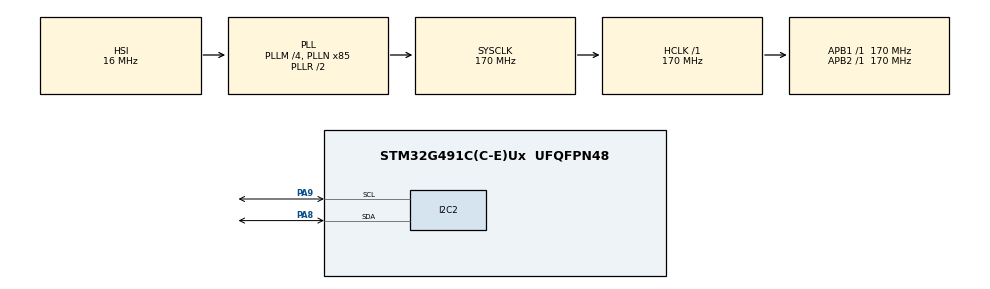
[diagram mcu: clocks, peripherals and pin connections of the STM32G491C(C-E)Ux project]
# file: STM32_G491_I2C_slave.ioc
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I2C2.OwnAddress=0x01
I2C2.Timing=0x30A0A7FB
Mcu.Family=STM32G4
Mcu.Name=STM32G491C(C-E)Ux
Mcu.Package=UFQFPN48
NVIC.I2C2_ER_IRQn=true\:0\:0\:false\:false\:true\:true\:true
NVIC.I2C2_EV_IRQn=true\:0\:0\:false\:false\:true\:true\:true
NVIC.PriorityGroup=NVIC_PRIORITYGROUP_4
PA8.Mode=I2C
PA8.Signal=I2C2_SDA
PA9.Mode=I2C
PA9.Signal=I2C2_SCL
ProjectManager.HeapSize=0x200
ProjectManager.StackSize=0x400
ProjectManager.TargetToolchain=STM32CubeIDE
RCC.ADC12Freq_Value=170000000
RCC.ADC345Freq_Value=170000000
RCC.AHBFreq_Value=170000000
RCC.APB1Freq_Value=170000000
RCC.APB1TimFreq_Value=170000000
RCC.APB2Freq_Value=170000000
RCC.APB2TimFreq_Value=170000000
RCC.CortexFreq_Value=170000000
RCC.EXTERNAL_CLOCK_VALUE=12288000
RCC.HCLKFreq_Value=170000000
RCC.HSE_VALUE=8000000
RCC.HSI48_VALUE=48000000
RCC.HSI_VALUE=16000000
RCC.LSE_VALUE=32768
RCC.PLLM=RCC_PLLM_DIV4
RCC.PLLN=85
RCC.SYSCLKFreq_VALUE=170000000
RCC.SYSCLKSource=RCC_SYSCLKSOURCE_PLLCLK
RCC.USBFreq_Value=48000000
RCC.VCOOutputFreq_Value=340000000
VP_SYS_VS_DBSignals.Mode=DisableDeadBatterySignals
board=custom

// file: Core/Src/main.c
/* USER CODE BEGIN Header */
/**
  ******************************************************************************
  * @file           : main.c
  * @brief          : Main program body
  ******************************************************************************
  * @attention
  *
  * <h2><center>&copy; Copyright (c) 2022 STMicroelectronics.
  * All rights reserved.</center></h2>
  *
  * This software component is licensed by ST under BSD 3-Clause license,
  * the "License"; You may not use this file except in compliance with the
  * License. You may obtain a copy of the License at:
  *                        opensource.org/licenses/BSD-3-Clause
  *
  ******************************************************************************
  */
/* USER CODE END Header */
#include "main.h"

I2C_HandleTypeDef hi2c2;

/* USER CODE BEGIN PV */
uint8_t Buffer[1] = {0};
/* USER CODE END PV */

void SystemClock_Config(void);
static void MX_GPIO_Init(void);
static void MX_I2C2_Init(void);

int main(void)
{

  /* MCU Configuration--------------------------------------------------------*/

  /* Reset of all peripherals, Initializes the Flash interface and the Systick. */
  HAL_Init();

  /* Configure the system clock */
  SystemClock_Config();

  /* Initialize all configured peripherals */
  MX_GPIO_Init();
  MX_I2C2_Init();
  /* USER CODE BEGIN 2 */
  //HAL_I2C_Slave_Receive_DMA(&hi2c2, (uint8_t*)Buffer, 1);
  HAL_I2C_Slave_Receive_IT(&hi2c2, (uint8_t*)Buffer, 1);
  uint8_t b = 0;
  /* USER CODE END 2 */

  /* Infinite loop */
  while (1)
  {

  }
}

void SystemClock_Config(void)
{
  RCC_OscInitTypeDef RCC_OscInitStruct = {0};
  RCC_ClkInitTypeDef RCC_ClkInitStruct = {0};
  RCC_PeriphCLKInitTypeDef PeriphClkInit = {0};

  /** Configure the main internal regulator output voltage
  */
  HAL_PWREx_ControlVoltageScaling(PWR_REGULATOR_VOLTAGE_SCALE1_BOOST);
  /** Initializes the RCC Oscillators according to the specified parameters
  * in the RCC_OscInitTypeDef structure.
  */
  RCC_OscInitStruct.OscillatorType = RCC_OSCILLATORTYPE_HSI;
  RCC_OscInitStruct.HSIState = RCC_HSI_ON;
  RCC_OscInitStruct.HSICalibrationValue = RCC_HSICALIBRATION_DEFAULT;
  RCC_OscInitStruct.PLL.PLLState = RCC_PLL_ON;
  RCC_OscInitStruct.PLL.PLLSource = RCC_PLLSOURCE_HSI;
  RCC_OscInitStruct.PLL.PLLM = RCC_PLLM_DIV4;
  RCC_OscInitStruct.PLL.PLLN = 85;
  RCC_OscInitStruct.PLL.PLLP = RCC_PLLP_DIV2;
  RCC_OscInitStruct.PLL.PLLQ = RCC_PLLQ_DIV2;
  RCC_OscInitStruct.PLL.PLLR = RCC_PLLR_DIV2;
  if (HAL_RCC_OscConfig(&RCC_OscInitStruct) != HAL_OK)
  {
    Error_Handler();
  }
  /** Initializes the CPU, AHB and APB buses clocks
  */
  RCC_ClkInitStruct.ClockType = RCC_CLOCKTYPE_HCLK|RCC_CLOCKTYPE_SYSCLK
                              |RCC_CLOCKTYPE_PCLK1|RCC_CLOCKTYPE_PCLK2;
  RCC_ClkInitStruct.SYSCLKSource = RCC_SYSCLKSOURCE_PLLCLK;
  RCC_ClkInitStruct.AHBCLKDivider = RCC_SYSCLK_DIV1;
  RCC_ClkInitStruct.APB1CLKDivider = RCC_HCLK_DIV1;
  RCC_ClkInitStruct.APB2CLKDivider = RCC_HCLK_DIV1;

  if (HAL_RCC_ClockConfig(&RCC_ClkInitStruct, FLASH_LATENCY_4) != HAL_OK)
  {
    Error_Handler();
  }
  /** Initializes the peripherals clocks
  */
  PeriphClkInit.I2c2ClockSelection = RCC_I2C2CLKSOURCE_PCLK1;
  if (HAL_RCCEx_PeriphCLKConfig(&PeriphClkInit) != HAL_OK)
  {
    Error_Handler();
  }
}

static void MX_I2C2_Init(void)
{

  hi2c2.Instance = I2C2;
  hi2c2.Init.Timing = 0x30A0A7FB;
  hi2c2.Init.OwnAddress1 = 2;
  hi2c2.Init.AddressingMode = I2C_ADDRESSINGMODE_7BIT;
  hi2c2.Init.DualAddressMode = I2C_DUALADDRESS_DISABLE;
  hi2c2.Init.OwnAddress2 = 0;
  hi2c2.Init.OwnAddress2Masks = I2C_OA2_NOMASK;
  hi2c2.Init.GeneralCallMode = I2C_GENERALCALL_DISABLE;
  hi2c2.Init.NoStretchMode = I2C_NOSTRETCH_DISABLE;
  if (HAL_I2C_Init(&hi2c2) != HAL_OK)
  {
    Error_Handler();
  }
  /** Configure Analogue filter
  */
  if (HAL_I2CEx_ConfigAnalogFilter(&hi2c2, I2C_ANALOGFILTER_ENABLE) != HAL_OK)
  {
    Error_Handler();
  }
  /** Configure Digital filter
  */
  if (HAL_I2CEx_ConfigDigitalFilter(&hi2c2, 0) != HAL_OK)
  {
    Error_Handler();
  }

}

static void MX_GPIO_Init(void)
{

  /* GPIO Ports Clock Enable */
  __HAL_RCC_GPIOA_CLK_ENABLE();

}

/* USER CODE BEGIN 4 */
void HAL_I2C_SlaveRxCpltCallback(I2C_HandleTypeDef *hi2c) {
  //HAL_I2C_Slave_Transmit_DMA(hi2c, (uint8_t*)Buffer, 1);
  HAL_I2C_Slave_Transmit(hi2c, (uint8_t*)Buffer, 1, 1000);
  uint8_t a = 10;
  HAL_I2C_Slave_Receive_IT(&hi2c2, (uint8_t*)Buffer, 1);
}

/*
void HAL_I2C_SlaveTxCpltCallback(I2C_HandleTypeDef *hi2c) {
  HAL_I2C_Slave_Receive_DMA(hi2c, (uint8_t*)Buffer, 1);
}
*/
/* USER CODE END 4 */

void Error_Handler(void)
{
  __disable_irq();
  while (1)
  {
  }
}

/************************ (C) COPYRIGHT STMicroelectronics *****END OF FILE****/
